VERSION ""

NS_ :

BS_:

BU_:

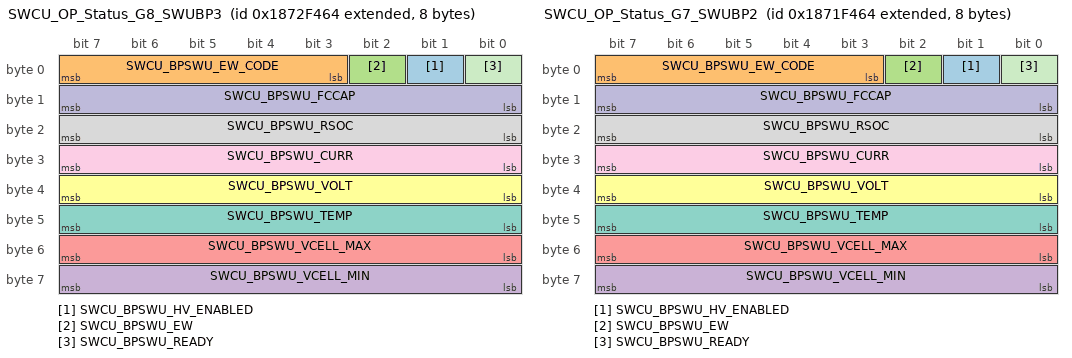
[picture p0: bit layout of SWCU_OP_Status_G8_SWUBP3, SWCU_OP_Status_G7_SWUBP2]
BO_ 2557670500 SWCU_OP_Status_G8_SWUBP3: 8 Vector__XXX
 SG_ SWCU_BPSWU_HV_ENABLED : 1|1@1+ (1,0) [0|0] "" Vector__XXX
 SG_ SWCU_BPSWU_EW_CODE : 3|5@1+ (1,0) [0|0] "" Vector__XXX
 SG_ SWCU_BPSWU_EW : 2|1@1+ (1,0) [0|0] "" Vector__XXX
 SG_ SWCU_BPSWU_VCELL_MIN : 56|8@1+ (0.01,2) [0|0] "V" Vector__XXX
 SG_ SWCU_BPSWU_VCELL_MAX : 48|8@1+ (0.01,2) [0|0] "V" Vector__XXX
 SG_ SWCU_BPSWU_VOLT : 32|8@1+ (1,0) [0|0] "V" Vector__XXX
 SG_ SWCU_BPSWU_TEMP : 40|8@1+ (1,-40) [0|0] "¢J" Vector__XXX
 SG_ SWCU_BPSWU_RSOC : 16|8@1+ (0.5,-12.5) [0|0] "%" Vector__XXX
 SG_ SWCU_BPSWU_CURR : 24|8@1+ (0.8,-100) [0|0] "A" Vector__XXX
 SG_ SWCU_BPSWU_FCCAP : 8|8@1+ (0.4,0) [0|0] "Ah" Vector__XXX
 SG_ SWCU_BPSWU_READY : 0|1@1+ (1,0) [0|0] "" Vector__XXX

BO_ 2557604964 SWCU_OP_Status_G7_SWUBP2: 8 Vector__XXX
 SG_ SWCU_BPSWU_HV_ENABLED : 1|1@1+ (1,0) [0|0] "" Vector__XXX
 SG_ SWCU_BPSWU_EW_CODE : 3|5@1+ (1,0) [0|0] "" Vector__XXX
 SG_ SWCU_BPSWU_EW : 2|1@1+ (1,0) [0|0] "" Vector__XXX
 SG_ SWCU_BPSWU_VCELL_MIN : 56|8@1+ (0.01,2) [0|0] "V" Vector__XXX
 SG_ SWCU_BPSWU_VCELL_MAX : 48|8@1+ (0.01,2) [0|0] "V" Vector__XXX
 SG_ SWCU_BPSWU_VOLT : 32|8@1+ (1,0) [0|0] "V" Vector__XXX
 SG_ SWCU_BPSWU_TEMP : 40|8@1+ (1,-40) [0|0] "¢J" Vector__XXX
 SG_ SWCU_BPSWU_RSOC : 16|8@1+ (0.5,-12.5) [0|0] "%" Vector__XXX
 SG_ SWCU_BPSWU_CURR : 24|8@1+ (0.8,-100) [0|0] "A" Vector__XXX
 SG_ SWCU_BPSWU_FCCAP : 8|8@1+ (0.4,0) [0|0] "Ah" Vector__XXX
 SG_ SWCU_BPSWU_READY : 0|1@1+ (1,0) [0|0] "" Vector__XXX

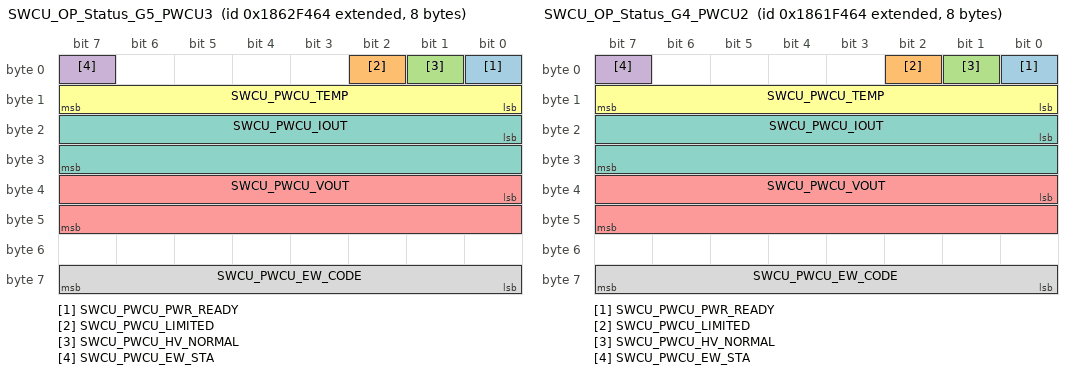
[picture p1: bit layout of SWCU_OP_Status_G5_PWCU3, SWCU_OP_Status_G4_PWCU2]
BO_ 2556621924 SWCU_OP_Status_G5_PWCU3: 8 Vector__XXX
 SG_ SWCU_PWCU_PWR_READY : 0|1@1+ (1,0) [0|0] "" Vector__XXX
 SG_ SWCU_PWCU_LIMITED : 2|1@1+ (1,0) [0|0] "" Vector__XXX
 SG_ SWCU_PWCU_HV_NORMAL : 1|1@1+ (1,0) [0|0] "" Vector__XXX
 SG_ SWCU_PWCU_EW_STA : 7|1@1+ (1,0) [0|0] "" Vector__XXX
 SG_ SWCU_PWCU_VOUT : 32|16@1+ (0.01,0) [0|0] "V" Vector__XXX
 SG_ SWCU_PWCU_TEMP : 8|8@1+ (1,-40) [0|0] "¢J" Vector__XXX
 SG_ SWCU_PWCU_IOUT : 16|16@1+ (0.01,0) [0|0] "A" Vector__XXX
 SG_ SWCU_PWCU_EW_CODE : 56|8@1+ (1,0) [0|0] "" Vector__XXX

BO_ 2556556388 SWCU_OP_Status_G4_PWCU2: 8 Vector__XXX
 SG_ SWCU_PWCU_PWR_READY : 0|1@1+ (1,0) [0|0] "" Vector__XXX
 SG_ SWCU_PWCU_LIMITED : 2|1@1+ (1,0) [0|0] "" Vector__XXX
 SG_ SWCU_PWCU_HV_NORMAL : 1|1@1+ (1,0) [0|0] "" Vector__XXX
 SG_ SWCU_PWCU_EW_STA : 7|1@1+ (1,0) [0|0] "" Vector__XXX
 SG_ SWCU_PWCU_VOUT : 32|16@1+ (0.01,0) [0|0] "V" Vector__XXX
 SG_ SWCU_PWCU_TEMP : 8|8@1+ (1,-40) [0|0] "¢J" Vector__XXX
 SG_ SWCU_PWCU_IOUT : 16|16@1+ (0.01,0) [0|0] "A" Vector__XXX
 SG_ SWCU_PWCU_EW_CODE : 56|8@1+ (1,0) [0|0] "" Vector__XXX

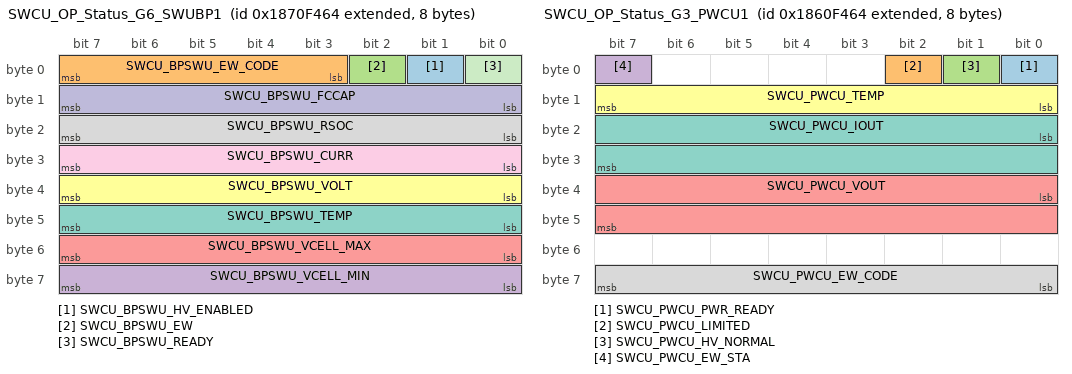
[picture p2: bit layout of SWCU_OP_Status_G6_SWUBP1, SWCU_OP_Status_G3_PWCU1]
BO_ 2557539428 SWCU_OP_Status_G6_SWUBP1: 8 Vector__XXX
 SG_ SWCU_BPSWU_HV_ENABLED : 1|1@1+ (1,0) [0|0] "" Vector__XXX
 SG_ SWCU_BPSWU_EW_CODE : 3|5@1+ (1,0) [0|0] "" Vector__XXX
 SG_ SWCU_BPSWU_EW : 2|1@1+ (1,0) [0|0] "" Vector__XXX
 SG_ SWCU_BPSWU_VCELL_MIN : 56|8@1+ (0.01,2) [0|0] "V" Vector__XXX
 SG_ SWCU_BPSWU_VCELL_MAX : 48|8@1+ (0.01,2) [0|0] "V" Vector__XXX
 SG_ SWCU_BPSWU_VOLT : 32|8@1+ (1,0) [0|0] "V" Vector__XXX
 SG_ SWCU_BPSWU_TEMP : 40|8@1+ (1,-40) [0|0] "¢J" Vector__XXX
 SG_ SWCU_BPSWU_RSOC : 16|8@1+ (0.5,-12.5) [0|0] "%" Vector__XXX
 SG_ SWCU_BPSWU_CURR : 24|8@1+ (0.8,-100) [0|0] "A" Vector__XXX
 SG_ SWCU_BPSWU_FCCAP : 8|8@1+ (0.4,0) [0|0] "Ah" Vector__XXX
 SG_ SWCU_BPSWU_READY : 0|1@1+ (1,0) [0|0] "" Vector__XXX

BO_ 2556490852 SWCU_OP_Status_G3_PWCU1: 8 Vector__XXX
 SG_ SWCU_PWCU_PWR_READY : 0|1@1+ (1,0) [0|0] "" Vector__XXX
 SG_ SWCU_PWCU_LIMITED : 2|1@1+ (1,0) [0|0] "" Vector__XXX
 SG_ SWCU_PWCU_HV_NORMAL : 1|1@1+ (1,0) [0|0] "" Vector__XXX
 SG_ SWCU_PWCU_EW_STA : 7|1@1+ (1,0) [0|0] "" Vector__XXX
 SG_ SWCU_PWCU_VOUT : 32|16@1+ (0.01,0) [0|0] "V" Vector__XXX
 SG_ SWCU_PWCU_TEMP : 8|8@1+ (1,-40) [0|0] "¢J" Vector__XXX
 SG_ SWCU_PWCU_IOUT : 16|16@1+ (0.01,0) [0|0] "A" Vector__XXX
 SG_ SWCU_PWCU_EW_CODE : 56|8@1+ (1,0) [0|0] "" Vector__XXX

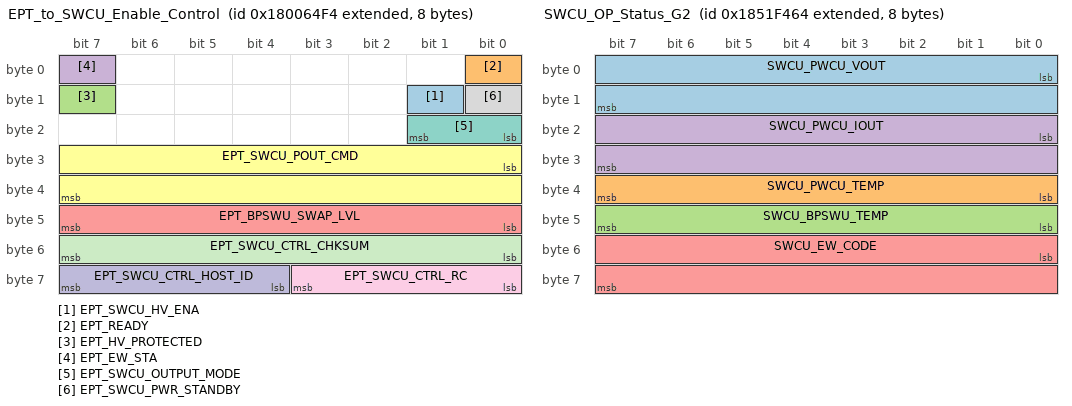
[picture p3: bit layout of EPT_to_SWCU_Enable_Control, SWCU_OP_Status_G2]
BO_ 2550162676 EPT_to_SWCU_Enable_Control: 8 Vector__XXX
 SG_ EPT_SWCU_HV_ENA : 9|1@1+ (1,0) [0|0] "" Vector__XXX
 SG_ EPT_READY : 0|1@1+ (1,0) [0|0] "" Vector__XXX
 SG_ EPT_HV_PROTECTED : 15|1@1+ (1,0) [0|0] "" Vector__XXX
 SG_ EPT_EW_STA : 7|1@1+ (1,0) [0|0] "" Vector__XXX
 SG_ EPT_BPSWU_SWAP_LVL : 40|8@1+ (0.5,0) [0|0] "%" Vector__XXX
 SG_ EPT_SWCU_POUT_CMD : 24|16@1+ (0.001,0) [0|0] "kw" Vector__XXX
 SG_ EPT_SWCU_OUTPUT_MODE : 16|2@1+ (1,0) [0|0] "" Vector__XXX
 SG_ EPT_SWCU_PWR_STANDBY : 8|1@1+ (1,0) [0|0] "" Vector__XXX
 SG_ EPT_SWCU_CTRL_RC : 56|4@1+ (1,0) [0|0] "" Vector__XXX
 SG_ EPT_SWCU_CTRL_HOST_ID : 60|4@1+ (1,0) [0|0] "" Vector__XXX
 SG_ EPT_SWCU_CTRL_CHKSUM : 48|8@1+ (1,0) [0|0] "" Vector__XXX

BO_ 2555507812 SWCU_OP_Status_G2: 8 Vector__XXX
 SG_ SWCU_PWCU_VOUT : 0|16@1+ (0.01,0) [0|0] "V" Vector__XXX
 SG_ SWCU_PWCU_TEMP : 32|8@1+ (1,-40) [0|0] "¢J" Vector__XXX
 SG_ SWCU_BPSWU_TEMP : 40|8@1+ (1,-40) [0|0] "¢J" Vector__XXX
 SG_ SWCU_PWCU_IOUT : 16|16@1+ (0.01,0) [0|0] "A" Vector__XXX
 SG_ SWCU_EW_CODE : 48|16@1+ (1,0) [0|0] "" Vector__XXX

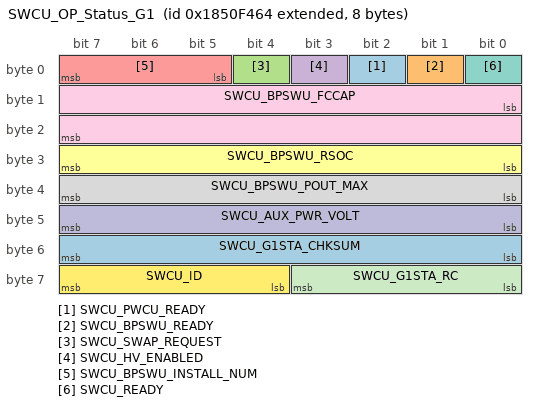
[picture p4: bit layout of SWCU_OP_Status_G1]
BO_ 2555442276 SWCU_OP_Status_G1: 8 Vector__XXX
 SG_ SWCU_PWCU_READY : 2|1@1+ (1,0) [0|0] "" Vector__XXX
 SG_ SWCU_BPSWU_READY : 1|1@1+ (1,0) [0|0] "" Vector__XXX
 SG_ SWCU_SWAP_REQUEST : 4|1@1+ (1,0) [0|0] "" Vector__XXX
 SG_ SWCU_HV_ENABLED : 3|1@1+ (1,0) [0|0] "" Vector__XXX
 SG_ SWCU_BPSWU_INSTALL_NUM : 5|3@1+ (1,0) [0|0] "" Vector__XXX
 SG_ SWCU_BPSWU_RSOC : 24|8@1+ (1,0) [0|0] "%" Vector__XXX
 SG_ SWCU_READY : 0|1@1+ (1,0) [0|0] "" Vector__XXX
 SG_ SWCU_BPSWU_POUT_MAX : 32|8@1+ (0.1,0) [0|25.5] "kw" Vector__XXX
 SG_ SWCU_BPSWU_FCCAP : 8|16@1+ (1,0) [0|0] "Ah" Vector__XXX
 SG_ SWCU_AUX_PWR_VOLT : 40|8@1+ (1,0) [0|0] "" Vector__XXX
 SG_ SWCU_G1STA_RC : 56|4@1+ (1,0) [0|0] "" Vector__XXX
 SG_ SWCU_ID : 60|4@1+ (1,0) [0|0] "" Vector__XXX
 SG_ SWCU_G1STA_CHKSUM : 48|8@1+ (1,0) [0|0] "" Vector__XXX
